AUTOSAR XML (schema 00046)
package /ComponentTypes
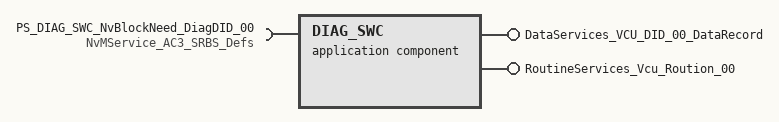
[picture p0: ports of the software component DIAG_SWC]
  application sw component type DIAG_SWC
    provide port DataServices_VCU_DID_00_DataRecord: provided-interface=DataServices_VCU_DID_00_DataRecord
      provided-com-specs:
        operation=ReadData, queue-length=1
        operation=ConditionCheckRead, queue-length=1
        operation=WriteData, queue-length=1
    require port PS_DIAG_SWC_NvBlockNeed_DiagDID_00: required-com-specs=[GetErrorStatus, SetRamBlockStatus, ReadBlock, WriteBlock, RestoreBlockDefaults, InvalidateNvBlock, EraseBlock], required-interface=NvMService_AC3_SRBS_Defs
    provide port RoutineServices_Vcu_Roution_00: provided-interface=RoutineServices_Vcu_Roution_00
      provided-com-specs:
        operation=Start, queue-length=1
        operation=Stop, queue-length=1
        operation=RequestResults, queue-length=1
    behavior DIAG_SWC_InternalBehavior
      ar-typed-per-instance-memorys:
        data NvBlockNeed_DiagDID_00_MirrorBlock: sw-calibration-access=READ-ONLY, type=NvM_Arry4Bytes
      6 x operation invoked event:
        OIT_DataServices_VCU_DID_00_DataRecord_WriteData_DataServices_VCU_DID_00_DataRecord_WriteData: start-on-event=DataServices_VCU_DID_00_DataRecord_WriteData, operation=DataServices_VCU_DID_00_DataRecord.WriteData
        OIT_DataServices_VCU_DID_00_DataRecord_ConditionCheckRead_DataServices_VCU_DID_00_DataRecord_ConditionCheckRead: start-on-event=DataServices_VCU_DID_00_DataRecord_ConditionCheckRead, operation=DataServices_VCU_DID_00_DataRecord.ConditionCheckRead
        OIT_DataServices_VCU_DID_00_DataRecord_ReadData_DataServices_VCU_DID_00_DataRecord_ReadData: start-on-event=DataServices_VCU_DID_00_DataRecord_ReadData, operation=DataServices_VCU_DID_00_DataRecord.ReadData
        OIT_RoutineServices_Vcu_Roution_00_RequestResults_RoutineServices_Vcu_Roution_00_RequestResults: start-on-event=RoutineServices_Vcu_Roution_00_RequestResults, operation=RoutineServices_Vcu_Roution_00.RequestResults
        OIT_RoutineServices_Vcu_Roution_00_Stop_RoutineServices_Vcu_Roution_00_Stop: start-on-event=RoutineServices_Vcu_Roution_00_Stop, operation=RoutineServices_Vcu_Roution_00.Stop
        OIT_RoutineServices_Vcu_Roution_00_Start_RoutineServices_Vcu_Roution_00_Start: start-on-event=RoutineServices_Vcu_Roution_00_Start, operation=RoutineServices_Vcu_Roution_00.Start
      6 x runnable:
        DataServices_VCU_DID_00_DataRecord_WriteData
          sync call SC_PS_DIAG_SWC_NvBlockNeed_DiagDID_00_GetErrorStatus: operation=PS_DIAG_SWC_NvBlockNeed_DiagDID_00.GetErrorStatus
          sync call SC_PS_DIAG_SWC_NvBlockNeed_DiagDID_00_SetRamBlockStatus: operation=PS_DIAG_SWC_NvBlockNeed_DiagDID_00.SetRamBlockStatus
          sync call SC_PS_DIAG_SWC_NvBlockNeed_DiagDID_00_WriteBlock: operation=PS_DIAG_SWC_NvBlockNeed_DiagDID_00.WriteBlock
        DataServices_VCU_DID_00_DataRecord_ConditionCheckRead
          sync call SC_PS_DIAG_SWC_NvBlockNeed_DiagDID_00_GetErrorStatus: operation=PS_DIAG_SWC_NvBlockNeed_DiagDID_00.GetErrorStatus
        DataServices_VCU_DID_00_DataRecord_ReadData
          sync call SC_PS_DIAG_SWC_NvBlockNeed_DiagDID_00_ReadBlock: operation=PS_DIAG_SWC_NvBlockNeed_DiagDID_00.ReadBlock
        RoutineServices_Vcu_Roution_00_RequestResults
        RoutineServices_Vcu_Roution_00_Stop
        RoutineServices_Vcu_Roution_00_Start
      swc service dependency NvBlockNeed_DiagDID_00
        assigned-datas:
          role=ramBlock, used-data-element=NvBlockNeed_DiagDID_00_MirrorBlock
          role=defaultValue, used-parameter-element=NvBlockNeed_DiagDID_00_DefaultValue
        service-needs:
          nv block needs NvBlockNeed_DiagDID_00: calc-ram-block-crc=false, check-static-block-id=false, n-data-sets=0, ram-block-status-control=API, readonly=false, reliability=ERROR-DETECTION, resistant-to-changed-sw=true, restore-at-start=true, store-at-shutdown=true, store-cyclic=false, store-emergency=false, store-immediate=false, use-auto-validation-at-shut-down=false, use-crc-comp-mechanism=false, write-only-once=false, write-verification=false
      shared-parameters:
        parameter data prototype NvBlockNeed_DiagDID_00_DefaultValue: sw-calibration-access=READ-WRITE, type=NvM_Arry4Bytes, init-value=[0, 0, 0, 0]
  swc implementation DIAG_SWC_Implementation: behavior=DIAG_SWC_InternalBehavior
